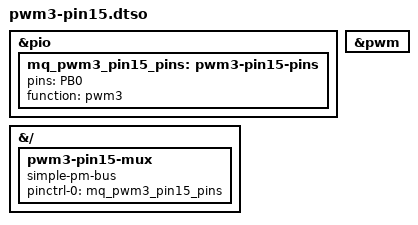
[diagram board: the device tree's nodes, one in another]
// SPDX-License-Identifier: (GPL-2.0+ OR MIT)
// Mangue OS header overlay pwm3-pin15 — GENERATED by tools/gen_overlays.py,
// edit overlays/header_table.py instead.
//
// pin port  role
//  15 PB0   pwm3
// device: /sys/class/pwm/pwmchip0 channel 3

/dts-v1/;
/plugin/;

#include <dt-bindings/gpio/gpio.h>
#include <dt-bindings/interrupt-controller/irq.h>
#include <dt-bindings/input/linux-event-codes.h>

&pio {
	mq_pwm3_pin15_pins: pwm3-pin15-pins {
		pins = "PB0";
		function = "pwm3";
	};
};

&pwm {
	status = "okay";
};

&{/} {
	pwm3-pin15-mux {
		compatible = "simple-pm-bus";
		pinctrl-names = "default";
		pinctrl-0 = <&mq_pwm3_pin15_pins>;
	};
};
